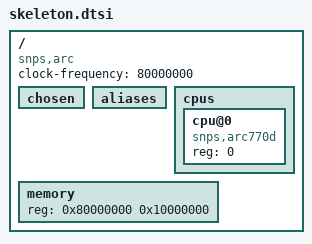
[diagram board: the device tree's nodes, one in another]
// SPDX-License-Identifier: GPL-2.0-only
/*
 * Copyright (C) 2012 Synopsys, Inc. (www.synopsys.com)
 */

/*
 * Skeleton device tree; the bare minimum needed to boot; just include and
 * add a compatible value.
 */

/ {
	compatible = "snps,arc";
	clock-frequency = <80000000>;	/* 80 MHZ */
	#address-cells = <1>;
	#size-cells = <1>;
	chosen { };
	aliases { };

	cpus {
		#address-cells = <1>;
		#size-cells = <0>;

		cpu@0 {
			device_type = "cpu";
			compatible = "snps,arc770d";
			reg = <0>;
		};
	};

	memory {
		device_type = "memory";
		reg = <0x80000000 0x10000000>;	/* 256M */
	};
};
